# APM32F40x register map
File version: 1.0
CPU: CM4 r1p0, little endian, no MPU, no FPU, 3 interrupt priority bits
Registers are 32-bit, read-write, reset 0x0 unless marked. A register's access mark holds for its fields unless they carry their own. Offsets are from the block's base; [hi:lo] are bit positions.

## DAC — Digital-to-analog converter
Base 0x40007400
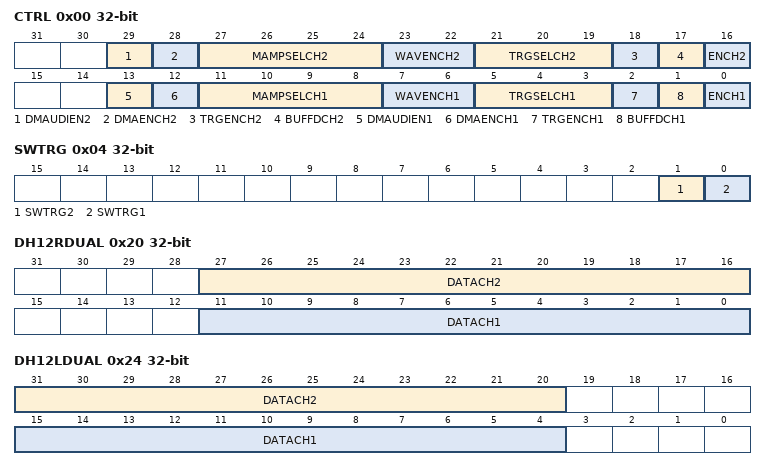
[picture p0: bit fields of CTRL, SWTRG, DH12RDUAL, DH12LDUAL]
0x00 CTRL — control register
  [29] DMAUDIEN2 — DAC channel2 DMA underrun interrupt enable
  [28] DMAENCH2 — DAC channel2 DMA enable
  [27:24] MAMPSELCH2 — DAC channel2 mask/amplitude selector
  [23:22] WAVENCH2 — DAC channel2 noise/triangle wave generation enable
  [21:19] TRGSELCH2 — DAC channel2 trigger selection
  [18] TRGENCH2 — DAC channel2 trigger enable
  [17] BUFFDCH2 — DAC channel2 output buffer disable
  [16] ENCH2 — DAC channel2 enable
  [13] DMAUDIEN1 — DAC channel1 DMA Underrun Interrupt enable
  [12] DMAENCH1 — DAC channel1 DMA enable
  [11:8] MAMPSELCH1 — DAC channel1 mask/amplitude selector
  [7:6] WAVENCH1 — DAC channel1 noise/triangle wave generation enable
  [5:3] TRGSELCH1 — DAC channel1 trigger selection
  [2] TRGENCH1 — DAC channel1 trigger enable
  [1] BUFFDCH1 — DAC channel1 output buffer disable
  [0] ENCH1 — DAC channel1 enable
0x04 SWTRG wo — software trigger register
  [1] SWTRG2 — DAC channel2 software trigger
  [0] SWTRG1 — DAC channel1 software trigger
0x08 DH12R1 — channel1 12-bit right-aligned data holding register
  [11:0] DATA — DAC channel1 12-bit right-aligned data
0x0C DH12L1 — channel1 12-bit left aligned data holding register
  [15:4] DATA — DAC channel1 12-bit left-aligned data
0x10 DH8R1 — channel1 8-bit right aligned data holding register
  [7:0] DATA — DAC channel1 8-bit right-aligned data
0x14 DH12R2 — channel2 12-bit right aligned data holding register
  [11:0] DATA — DAC channel2 12-bit right-aligned data
0x18 DH12L2 — channel2 12-bit left aligned data holding register
  [15:4] DATA — DAC channel2 12-bit left-aligned data
0x1C DH8R2 — channel2 8-bit right-aligned data holding register
  [7:0] DATA — DAC channel2 8-bit right-aligned data
0x20 DH12RDUAL — Dual DAC 12-bit right-aligned data holding register
  [27:16] DATACH2 — DAC channel2 12-bit right-aligned data
  [11:0] DATACH1 — DAC channel1 12-bit right-aligned data
0x24 DH12LDUAL — DUAL DAC 12-bit left aligned data holding register
  [31:20] DATACH2 — DAC channel2 12-bit left-aligned data
  [15:4] DATACH1 — DAC channel1 12-bit left-aligned data
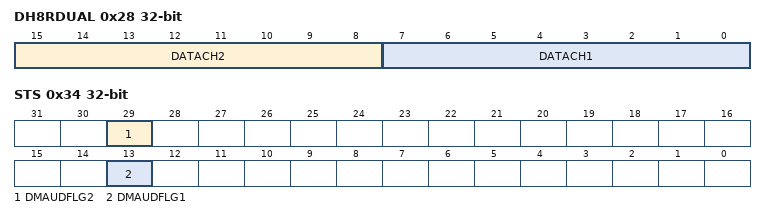
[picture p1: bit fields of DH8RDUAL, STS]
0x28 DH8RDUAL — DUAL DAC 8-bit right aligned data holding register
  [15:8] DATACH2 — DAC channel2 8-bit right-aligned data
  [7:0] DATACH1 — DAC channel1 8-bit right-aligned data
0x2C DATAOCH1 ro — channel1 data output register
  [11:0] DATA — DAC channel1 data output
0x30 DATAOCH2 ro — channel2 data output register
  [11:0] DATA — DAC channel2 data output
0x34 STS — status register
  [29] DMAUDFLG2 — DAC channel2 DMA underrun flag
  [13] DMAUDFLG1 — DAC channel1 DMA underrun flag

## PMU — Power control
Base 0x40007000
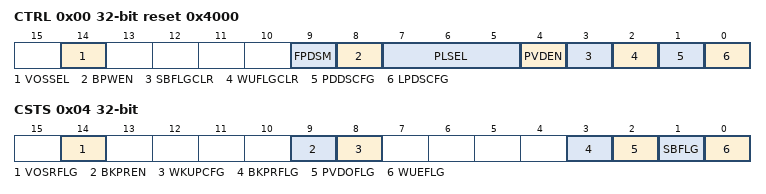
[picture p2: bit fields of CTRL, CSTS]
0x00 CTRL reset 0x4000 — power control register
  [14] VOSSEL — Regulator Voltage Scaling Output Selection
  [9] FPDSM — Flash power down in Stop mode
  [8] BPWEN — Disable backup domain write protection
  [7:5] PLSEL — PVD level selection
  [4] PVDEN — Power voltage detector enable
  [3] SBFLGCLR — Clear standby flag
  [2] WUFLGCLR — Clear wakeup flag
  [1] PDDSCFG — Power down deepsleep
  [0] LPDSCFG — Low-power deep sleep
0x04 CSTS access per field — power control/status register
  [14] VOSRFLG rw — Regulator voltage scaling output selection ready bit
  [9] BKPREN rw — Backup regulator enable
  [8] WKUPCFG rw — Enable WKUP pin
  [3] BKPRFLG ro — Backup regulator ready
  [2] PVDOFLG ro — PVD output
  [1] SBFLG ro — Standby flag
  [0] WUEFLG ro — Wakeup flag

## I2C3 — Inter-integrated circuit
Base 0x40005C00
Same registers: I2C1 0x40005400, I2C2 0x40005800
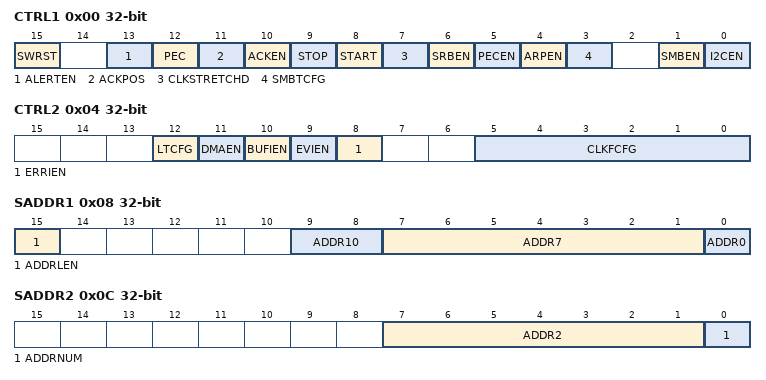
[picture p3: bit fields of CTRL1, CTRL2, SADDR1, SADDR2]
0x00 CTRL1 — Control register 1
  [15] SWRST — Software reset
  [13] ALERTEN — SMBus alert
  [12] PEC — Packet error checking
  [11] ACKPOS — Acknowledge/PEC Position (for data reception)
  [10] ACKEN — Acknowledge enable
  [9] STOP — Stop generation
  [8] START — Start generation
  [7] CLKSTRETCHD — Clock stretching disable (Slave mode)
  [6] SRBEN — General call enable
  [5] PECEN — PEC enable
  [4] ARPEN — ARP enable
  [3] SMBTCFG — SMBus type
  [1] SMBEN — SMBus mode
  [0] I2CEN — I2C enable
0x04 CTRL2 — Control register 2
  [12] LTCFG — DMA last transfer
  [11] DMAEN — DMA requests enable
  [10] BUFIEN — Buffer interrupt enable
  [9] EVIEN — Event interrupt enable
  [8] ERRIEN — Error interrupt enable
  [5:0] CLKFCFG — I2C clock frequency
0x08 SADDR1 — Own address register 1
  [15] ADDRLEN — Addressing mode (slave mode)
  [9:8] ADDR10 — Interface address
  [7:1] ADDR7 — Interface address
  [0] ADDR0 — Interface address
0x0C SADDR2 — Own address register 2
  [7:1] ADDR2 — Interface address
  [0] ADDRNUM — Slave Address Number Configure
0x10 DATA
  [7:0] DATA — 8-bit data register
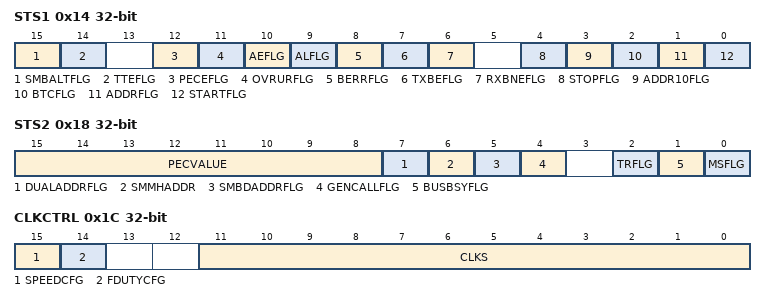
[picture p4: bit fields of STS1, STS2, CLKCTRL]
0x14 STS1 access per field — Status register 1
  [15] SMBALTFLG rw — SMBus alert
  [14] TTEFLG rw — Timeout or Tlow error
  [12] PECEFLG rw — PEC Error in reception
  [11] OVRURFLG rw — Overrun/Underrun
  [10] AEFLG rw — Acknowledge failure
  [9] ALFLG rw — Arbitration lost (master mode)
  [8] BERRFLG rw — Bus error
  [7] TXBEFLG ro — Data register empty (transmitters)
  [6] RXBNEFLG ro — Data register not empty (receivers)
  [4] STOPFLG ro — Stop detection (slave mode)
  [3] ADDR10FLG ro — 10-bit header sent (Master mode)
  [2] BTCFLG ro — Byte transfer finished
  [1] ADDRFLG ro — Address sent (master mode)/matched (slave mode)
  [0] STARTFLG ro — Start bit (Master mode)
0x18 STS2 ro — Status register 2
  [15:8] PECVALUE — Save Packet Error Checking Value
  [7] DUALADDRFLG — Dual flag (Slave mode)
  [6] SMMHADDR — SMBus host header (Slave mode)
  [5] SMBDADDRFLG — SMBus device default address (Slave mode)
  [4] GENCALLFLG — General call address (Slave mode)
  [2] TRFLG — Transmitter/receiver
  [1] BUSBSYFLG — Bus busy
  [0] MSFLG — Master Slave Mode Flag
0x1C CLKCTRL — Clock control register
  [15] SPEEDCFG — Master Mode Speed Configure
  [14] FDUTYCFG — Fast mode duty cycle
  [11:0] CLKS — Clock control register in Fast/Standard mode (Master mode)
0x20 RISETMAX reset 0x2 — Maximum Rise Time register
  [5:0] RISETMAX — Maximum rise time in Fast/Standard mode (Master mode)
